# YTM32B1MD2 register map
Vendor: YTMicro; File version: 1.0
CPU: CM33 r0p4, little endian, MPU, FPU, 2 interrupt priority bits
Registers are 32-bit, read-write, reset 0x0 unless marked. A register's access mark holds for its fields unless they carry their own. Offsets are from the block's base; [hi:lo] are bit positions.

## RTC — Real Time Clock provides a real time counter which is present in always on domain.
Base 0x40060000; register names take the prefix RTC_
0x00 SEC — RTC Second Register. This register bits is reset by Power-on Reset.
  [31:0] SEC — SEC is read-only when RTC is enabled. The SEC increments once a second provided INTF[OVFIF] is not set. The time counter will read as zero when INTF[OVFIF] is set. When RTC is disabled, SEC can be read and written. Writing to this bit will clear the INTF[OVFIF]. Writing to SEC with zero is not recommended because SEC will read as zero when INTF[OVFIF] is set.
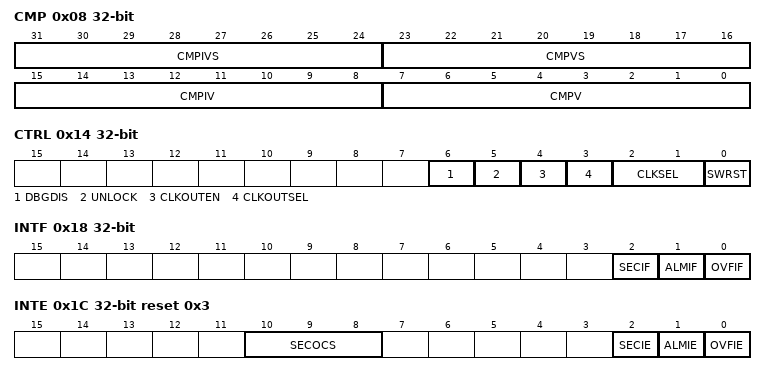
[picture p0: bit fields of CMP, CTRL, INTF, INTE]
0x08 CMP — RTC Compensation Register. This register bits is reset by Power-on Reset.
  [31:24] CMPIVS ro — Current value of the compensation interval counter. If the compensation interval counter equals zero then it is loaded with the contents of the CMPIV. If the CMPV does not equal zero then it is decremented once a second. Reading this register at the same time as the seconds counter is incrementing can result in an incorrect value being read.
  [23:16] CMPVS ro — Current value used by the compensation logic for the present second interval. Updated once a second if the CMPIVS equals 0 with the contents of the CMPV field. If the CMPIVS does not equal zero then it is loaded with zero (compensation is not enabled for that second increment). Reading this register at the same time as the seconds counter is incrementing can result in an incorrect value being read.
  [15:8] CMPIV — Configures the compensation interval in seconds from 1 to 256 to control how frequently the CMPV should adjust the number of 32.768 kHz cycles in each second. The value which is written should be one less than the number of seconds. For example, write zero to configure for a compensation interval of one second. This register is double-buffered and writes do not take effect until the end of the current compensation interval.
  [7:0] CMPV — Configures the number of 32.768 kHz clock cycles in each second, equal to 32,768 CMPV.CMPV is a twos complement sign-extended value. This register is double-buffered and writes do not take effect until the end of the current compensation interval. For example: 00000000b - The number of clock cycles in each second is 32768. 00000001b - The number of clock cycles in each second is 32767. 01111110b - The number of clock cycles in each second is 32642. 01111111b - The number of clock cycles in each second is 32641. 11111111b - The number of clock cycles in each second is 32769. 10000000b - The number of clock cycles in each second is 32896. 10000001b - The number of clock cycles in each second is 32895.
0x0C ALM — RTC Alarm Register. This register bits is reset by Power-on Reset.
  [31:0] ALM — If RTC is enabled, when ALM equals the SEC[SEC] and the SEC[SEC] increments, INTF[ALMIF] will set.
0x10 EN — RTC Enable Register. This register bits is reset by Power-on Reset.
  [0] EN — When RTC is disabled, SEC is writable. ewline When RTC is enabled, SEC is not writable.
    0=RTC disable; 1=RTC enable
0x14 CTRL — RTC Control Register. This register bits is reset by Power-on Reset.
  [6] DBGDIS — Default 0, run at debug mode.
    0=RTC keeps running in debug mode; 1=RTC stops in debug mode
  [5] UNLOCK — Unlock register access bit, allows RTC_EN register to be written
    0=Don't allow RTC_EN register to be written; 1=Allow RTC_EN register to be written
  [4] CLKOUTEN — Enable the RTC output clock, when CLKOUTEN is not set, rtc output clock is zero.
    0=RTC clock output disable; 1=RTC clock output enable
  [3] CLKOUTSEL
    0=RTC clock output is selected by configuration of CTRL[CLKSEL]; 1=1
  [2:1] CLKSEL
    0=PCLK RTC; 1=RTC CLKIN; 2=SIRC; 3=Functional clock from IPC
  [0] SWRST
    0=No effect; 1=Resets all RTC registers except SWRST which only cleared by POR and by software
0x18 INTF — RTC Interrupt Flag Register. This register bits is reset by Power-on Reset.
  [2] SECIF — RTC second interrupt flag. Write 1 to clear this flag.
    0=No second interrupt is pending; 1=The Second interrupt is pending
  [1] ALMIF ro — RTC alarm interrupt flag. Write ALM register to clear this flag.
    0=No alarm interrupt is pending; 1=Alarm interrupt is pending
  [0] OVFIF ro — RTC overflow interrupt flag. Write SEC register to clear this flag.
    0=No overflow interrupt is pending; 1=Overflow interrupt is pending
0x1C INTE reset 0x3 — RTC Interrupt Enable Register. This register bits is reset by Power-on Reset.
  [10:8] SECOCS — RTC Second output clock select
    0=Second output at 1Hz; 1=Second output at 2Hz; 2=Second output at 4Hz; 3=Second output at 8Hz; 4=Second output at 16Hz; 5=Second output at 32Hz; 6=Second output at 64Hz; 7=Second output at 128Hz
  [2] SECIE — RTC second interrupt enable bit
    0=Second interrupt disable; 1=Second interrupt enable
  [1] ALMIE
    0=Alarm interrupt disable; 1=Alarm interrupt enable
  [0] OVFIE
    0=Overflow interrupt disable; 1=Overflow interrupt enable
